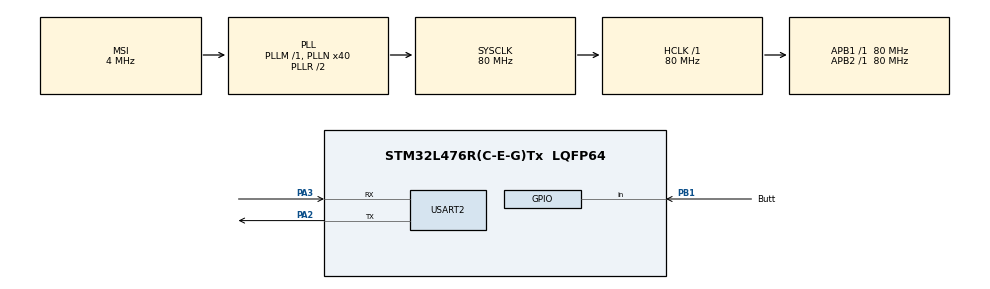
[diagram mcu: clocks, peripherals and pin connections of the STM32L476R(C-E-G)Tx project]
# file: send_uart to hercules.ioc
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Mcu.Family=STM32L4
Mcu.Name=STM32L476R(C-E-G)Tx
Mcu.Package=LQFP64
NVIC.PriorityGroup=NVIC_PRIORITYGROUP_4
PA13\ (JTMS-SWDIO).Mode=Serial_Wire
PA13\ (JTMS-SWDIO).Signal=SYS_JTMS-SWDIO
PA14\ (JTCK-SWCLK).Mode=Serial_Wire
PA14\ (JTCK-SWCLK).Signal=SYS_JTCK-SWCLK
PA2.Mode=Asynchronous
PA2.Signal=USART2_TX
PA3.Mode=Asynchronous
PA3.Signal=USART2_RX
PB1.GPIO_Label=Butt
PB1.GPIO_PuPd=GPIO_PULLUP
PB1.Signal=GPIO_Input
PH0-OSC_IN\ (PH0).Mode=HSE-External-Oscillator
PH0-OSC_IN\ (PH0).Signal=RCC_OSC_IN
PH1-OSC_OUT\ (PH1).Mode=HSE-External-Oscillator
PH1-OSC_OUT\ (PH1).Signal=RCC_OSC_OUT
ProjectManager.HeapSize=0x200
ProjectManager.StackSize=0x400
ProjectManager.TargetToolchain=STM32CubeIDE
RCC.AHBFreq_Value=80000000
RCC.APB1Freq_Value=80000000
RCC.APB1TimFreq_Value=80000000
RCC.APB2Freq_Value=80000000
RCC.APB2TimFreq_Value=80000000
RCC.CortexFreq_Value=80000000
RCC.HCLKFreq_Value=80000000
RCC.HSE_VALUE=8000000
RCC.HSI_VALUE=16000000
RCC.LSE_VALUE=32768
RCC.MSI_VALUE=4000000
RCC.PLLN=40
RCC.SYSCLKFreq_VALUE=80000000
RCC.SYSCLKSource=RCC_SYSCLKSOURCE_PLLCLK
RCC.VCOOutputFreq_Value=160000000
USART2.VirtualMode-Asynchronous=VM_ASYNC
board=custom

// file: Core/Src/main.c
/* USER CODE BEGIN Header */
/**
  ******************************************************************************
  * @file           : main.c
  * @brief          : Main program body
  ******************************************************************************
  * @attention
  *
  * Copyright (c) 2025 STMicroelectronics.
  * All rights reserved.
  *
  * This software is licensed under terms that can be found in the LICENSE file
  * in the root directory of this software component.
  * If no LICENSE file comes with this software, it is provided AS-IS.
  *
  ******************************************************************************
  */
/* USER CODE END Header */
#include "main.h"
#include <stdio.h> // For sprintf
#include <string.h> // For strlen

UART_HandleTypeDef huart2;

/* USER CODE BEGIN PV */
volatile uint32_t counter = 0;       // Counter variable
uint8_t buttonState = 0;             // Current button state
uint8_t lastButtonState = 0;         // Last button state
volatile char txBuffer[32] = {0};    // Buffer for UART transmission
/* USER CODE END PV */

void SystemClock_Config(void);
static void MX_GPIO_Init(void);
static void MX_USART2_UART_Init(void);

int main(void)
{

  /* MCU Configuration--------------------------------------------------------*/

  /* Reset of all peripherals, Initializes the Flash interface and the Systick. */
  HAL_Init();

  /* Configure the system clock */
  SystemClock_Config();

  /* Initialize all configured peripherals */
  MX_GPIO_Init();
  MX_USART2_UART_Init();

  /* Infinite loop */
  while (1)
  {
	  // Read button state (active-low)
	      buttonState = HAL_GPIO_ReadPin(GPIOB, GPIO_PIN_1);

	      // Detect button press (falling edge)
	      if (buttonState == 0 && lastButtonState == 1)
	      {
	        counter++; // Increment counter
	        sprintf((char*)txBuffer, "Counter: %lu\r\n", counter); // Format buffer
	        HAL_UART_Transmit(&huart2, (uint8_t*)txBuffer, strlen((char*)txBuffer), 100); // Send to UART
	        ITM_SendString((char*)txBuffer); // Send to SWV ITM
	        HAL_Delay(50); // Debounce delay
	      }
	      lastButtonState = buttonState;

  }
}

void SystemClock_Config(void)
{
  RCC_OscInitTypeDef RCC_OscInitStruct = {0};
  RCC_ClkInitTypeDef RCC_ClkInitStruct = {0};

  /** Configure the main internal regulator output voltage
  */
  if (HAL_PWREx_ControlVoltageScaling(PWR_REGULATOR_VOLTAGE_SCALE1) != HAL_OK)
  {
    Error_Handler();
  }

  /** Initializes the RCC Oscillators according to the specified parameters
  * in the RCC_OscInitTypeDef structure.
  */
  RCC_OscInitStruct.OscillatorType = RCC_OSCILLATORTYPE_MSI;
  RCC_OscInitStruct.MSIState = RCC_MSI_ON;
  RCC_OscInitStruct.MSICalibrationValue = 0;
  RCC_OscInitStruct.MSIClockRange = RCC_MSIRANGE_6;
  RCC_OscInitStruct.PLL.PLLState = RCC_PLL_ON;
  RCC_OscInitStruct.PLL.PLLSource = RCC_PLLSOURCE_MSI;
  RCC_OscInitStruct.PLL.PLLM = 1;
  RCC_OscInitStruct.PLL.PLLN = 40;
  RCC_OscInitStruct.PLL.PLLP = RCC_PLLP_DIV7;
  RCC_OscInitStruct.PLL.PLLQ = RCC_PLLQ_DIV2;
  RCC_OscInitStruct.PLL.PLLR = RCC_PLLR_DIV2;
  if (HAL_RCC_OscConfig(&RCC_OscInitStruct) != HAL_OK)
  {
    Error_Handler();
  }

  /** Initializes the CPU, AHB and APB buses clocks
  */
  RCC_ClkInitStruct.ClockType = RCC_CLOCKTYPE_HCLK|RCC_CLOCKTYPE_SYSCLK
                              |RCC_CLOCKTYPE_PCLK1|RCC_CLOCKTYPE_PCLK2;
  RCC_ClkInitStruct.SYSCLKSource = RCC_SYSCLKSOURCE_PLLCLK;
  RCC_ClkInitStruct.AHBCLKDivider = RCC_SYSCLK_DIV1;
  RCC_ClkInitStruct.APB1CLKDivider = RCC_HCLK_DIV1;
  RCC_ClkInitStruct.APB2CLKDivider = RCC_HCLK_DIV1;

  if (HAL_RCC_ClockConfig(&RCC_ClkInitStruct, FLASH_LATENCY_4) != HAL_OK)
  {
    Error_Handler();
  }
}

static void MX_USART2_UART_Init(void)
{

  huart2.Instance = USART2;
  huart2.Init.BaudRate = 115200;
  huart2.Init.WordLength = UART_WORDLENGTH_8B;
  huart2.Init.StopBits = UART_STOPBITS_1;
  huart2.Init.Parity = UART_PARITY_NONE;
  huart2.Init.Mode = UART_MODE_TX_RX;
  huart2.Init.HwFlowCtl = UART_HWCONTROL_NONE;
  huart2.Init.OverSampling = UART_OVERSAMPLING_16;
  huart2.Init.OneBitSampling = UART_ONE_BIT_SAMPLE_DISABLE;
  huart2.AdvancedInit.AdvFeatureInit = UART_ADVFEATURE_NO_INIT;
  if (HAL_UART_Init(&huart2) != HAL_OK)
  {
    Error_Handler();
  }

}

static void MX_GPIO_Init(void)
{
  GPIO_InitTypeDef GPIO_InitStruct = {0};

  /* GPIO Ports Clock Enable */
  __HAL_RCC_GPIOH_CLK_ENABLE();
  __HAL_RCC_GPIOA_CLK_ENABLE();
  __HAL_RCC_GPIOB_CLK_ENABLE();

  /*Configure GPIO pin : Butt_Pin */
  GPIO_InitStruct.Pin = Butt_Pin;
  GPIO_InitStruct.Mode = GPIO_MODE_INPUT;
  GPIO_InitStruct.Pull = GPIO_PULLUP;
  HAL_GPIO_Init(Butt_GPIO_Port, &GPIO_InitStruct);

}

/* USER CODE BEGIN 4 */
void ITM_SendString(char *str)
{
  while (*str != '\0')
  {
    ITM_SendChar(*str); // Send each character via ITM
    str++;
  }
}
/* USER CODE END 4 */

void Error_Handler(void)
{
  __disable_irq();
  while (1)
  {
  }
}
